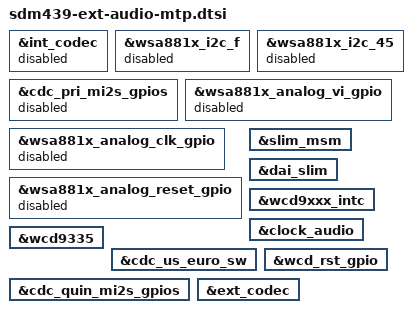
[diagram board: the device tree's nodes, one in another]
&int_codec {
	status = "disabled";
};

&wsa881x_i2c_f {
	status = "disabled";
};

&wsa881x_i2c_45 {
	status = "disabled";
};

&cdc_pri_mi2s_gpios {
	status = "disabled";
};

&wsa881x_analog_vi_gpio {
	status = "disabled";
};

&wsa881x_analog_clk_gpio {
	status = "disabled";
};

&wsa881x_analog_reset_gpio {
	status = "disabled";
};

&slim_msm {
	status = "okay";
};

&dai_slim {
	status = "okay";
};

&wcd9xxx_intc {
	status = "okay";
};

&clock_audio {
	status = "okay";
};

&wcd9335 {
	status = "okay";
};

&cdc_us_euro_sw {
	status = "okay";
};

&cdc_quin_mi2s_gpios {
	status = "okay";
};

&wcd_rst_gpio {
	status = "okay";
};

&ext_codec {
	status = "okay";
};

